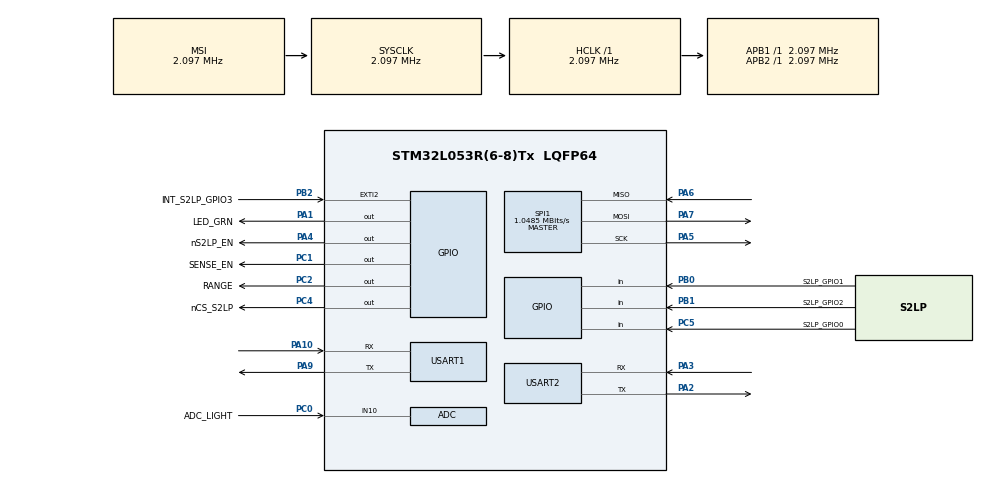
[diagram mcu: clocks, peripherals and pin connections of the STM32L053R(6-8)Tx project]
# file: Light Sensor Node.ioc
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Mcu.Family=STM32L0
Mcu.Name=STM32L053R(6-8)Tx
Mcu.Package=LQFP64
NVIC.EXTI2_3_IRQn=true\:0\:0\:false\:false\:true
NVIC.SPI1_IRQn=true\:0\:0\:false\:false\:true
PA1.GPIO_Label=LED_GRN
PA1.Signal=GPIO_Output
PA10.Mode=Asynchronous
PA10.Signal=USART1_RX
PA13.Mode=Serial_Wire
PA13.Signal=SYS_SWDIO
PA14.Mode=Serial_Wire
PA14.Signal=SYS_SWCLK
PA2.Mode=Asynchronous
PA2.Signal=USART2_TX
PA3.Mode=Asynchronous
PA3.Signal=USART2_RX
PA4.GPIO_Label=nS2LP_EN
PA4.Signal=GPIO_Output
PA5.Mode=Full_Duplex_Master
PA5.Signal=SPI1_SCK
PA6.Mode=Full_Duplex_Master
PA6.Signal=SPI1_MISO
PA7.Mode=Full_Duplex_Master
PA7.Signal=SPI1_MOSI
PA9.Mode=Asynchronous
PA9.Signal=USART1_TX
PB0.GPIO_Label=S2LP_GPIO1
PB0.Signal=GPIO_Input
PB1.GPIO_Label=S2LP_GPIO2
PB1.Signal=GPIO_Input
PB2.GPIO_Label=INT_S2LP_GPIO3
PB2.GPIO_ModeDefaultEXTI=GPIO_MODE_IT_FALLING
PB2.GPIO_PuPd=GPIO_PULLUP
PB2.Signal=GPXTI2
PC0.GPIO_Label=ADC_LIGHT
PC0.Mode=IN10
PC0.Signal=ADC_IN10
PC1.GPIO_Label=SENSE_EN
PC1.Signal=GPIO_Output
PC14-OSC32_IN.Mode=LSE-External-Oscillator
PC14-OSC32_IN.Signal=RCC_OSC32_IN
PC15-OSC32_OUT.Mode=LSE-External-Oscillator
PC15-OSC32_OUT.Signal=RCC_OSC32_OUT
PC2.GPIO_Label=RANGE
PC2.Signal=GPIO_Output
PC4.GPIO_Label=nCS_S2LP
PC4.PinState=GPIO_PIN_SET
PC4.Signal=GPIO_Output
PC5.GPIO_Label=S2LP_GPIO0
PC5.Signal=GPIO_Input
ProjectManager.HeapSize=0x200
ProjectManager.StackSize=0x400
ProjectManager.TargetToolchain=MDK-ARM V5
RCC.AHBFreq_Value=2097000
RCC.APB1Freq_Value=2097000
RCC.APB1TimFreq_Value=2097000
RCC.APB2Freq_Value=2097000
RCC.APB2TimFreq_Value=2097000
RCC.HSE_VALUE=8000000
RCC.HSI16_VALUE=16000000
RCC.HSI48_VALUE=48000000
RCC.HSI_VALUE=16000000
RCC.MSI_VALUE=2097000
RCC.RTCClockSelection=RCC_RTCCLKSOURCE_LSE
RCC.RTCClockSelectionVirtual=RCC_RTCCLKSOURCE_LSE
RCC.SYSCLKFreq_VALUE=2097000
RCC.VCOOutputFreq_Value=48000000
SPI1.CalculateBaudRate=1.0485 MBits/s
SPI1.Direction=SPI_DIRECTION_2LINES
SPI1.Mode=SPI_MODE_MASTER
SPI1.VirtualType=VM_MASTER
USART1.VirtualMode-Asynchronous=VM_ASYNC
USART1.WordLength=WORDLENGTH_8B
USART2.VirtualMode-Asynchronous=VM_ASYNC
USART2.WordLength=WORDLENGTH_8B
VP_ADC_TempSens_Input.Mode=IN-TempSens
VP_ADC_Vref_Input.Mode=IN-Vrefint
VP_RTC_VS_RTC_Activate.Mode=RTC_Enabled
VP_RTC_VS_RTC_Calendar.Mode=RTC_Calendar
board=Light Sensor Node

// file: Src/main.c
/**
  ******************************************************************************
  * File Name          : main.c
  * Description        : Main program body
  ******************************************************************************
  ** This notice applies to any and all portions of this file
  * that are not between comment pairs USER CODE BEGIN and
  * USER CODE END. Other portions of this file, whether
  * inserted by the user or by software development tools
  * are owned by their respective copyright owners.
  *
  * COPYRIGHT(c) 2018 STMicroelectronics
  *
  * Redistribution and use in source and binary forms, with or without modification,
  * are permitted provided that the following conditions are met:
  *   1. Redistributions of source code must retain the above copyright notice,
  *      this list of conditions and the following disclaimer.
  *   2. Redistributions in binary form must reproduce the above copyright notice,
  *      this list of conditions and the following disclaimer in the documentation
  *      and/or other materials provided with the distribution.
  *   3. Neither the name of STMicroelectronics nor the names of its contributors
  *      may be used to endorse or promote products derived from this software
  *      without specific prior written permission.
  *
  * THIS SOFTWARE IS PROVIDED BY THE COPYRIGHT HOLDERS AND CONTRIBUTORS "AS IS"
  * AND ANY EXPRESS OR IMPLIED WARRANTIES, INCLUDING, BUT NOT LIMITED TO, THE
  * IMPLIED WARRANTIES OF MERCHANTABILITY AND FITNESS FOR A PARTICULAR PURPOSE ARE
  * DISCLAIMED. IN NO EVENT SHALL THE COPYRIGHT HOLDER OR CONTRIBUTORS BE LIABLE
  * FOR ANY DIRECT, INDIRECT, INCIDENTAL, SPECIAL, EXEMPLARY, OR CONSEQUENTIAL
  * DAMAGES (INCLUDING, BUT NOT LIMITED TO, PROCUREMENT OF SUBSTITUTE GOODS OR
  * SERVICES; LOSS OF USE, DATA, OR PROFITS; OR BUSINESS INTERRUPTION) HOWEVER
  * CAUSED AND ON ANY THEORY OF LIABILITY, WHETHER IN CONTRACT, STRICT LIABILITY,
  * OR TORT (INCLUDING NEGLIGENCE OR OTHERWISE) ARISING IN ANY WAY OUT OF THE USE
  * OF THIS SOFTWARE, EVEN IF ADVISED OF THE POSSIBILITY OF SUCH DAMAGE.
  *
  ******************************************************************************
  */
#include "main.h"
#include "stm32l0xx_hal.h"

/* USER CODE BEGIN Includes */
#include "mg_S2lpTopLevel.h"

/* USER CODE END Includes */

ADC_HandleTypeDef hadc;

RTC_HandleTypeDef hrtc;

SPI_HandleTypeDef hspi1;

UART_HandleTypeDef huart1;
UART_HandleTypeDef huart2;

/* USER CODE BEGIN PV */
/* Private variables ---------------------------------------------------------*/

/* USER CODE END PV */

void SystemClock_Config(void);
static void MX_GPIO_Init(void);
static void MX_ADC_Init(void);
static void MX_SPI1_Init(void);
static void MX_USART1_UART_Init(void);
static void MX_RTC_Init(void);
static void MX_USART2_UART_Init(void);

/* USER CODE BEGIN PFP */
/* Private function prototypes -----------------------------------------------*/

/* USER CODE END PFP */

int main(void)
{

  /* MCU Configuration----------------------------------------------------------*/

  /* Reset of all peripherals, Initializes the Flash interface and the Systick. */
  HAL_Init();

  /* Configure the system clock */
  SystemClock_Config();

  /* Initialize all configured peripherals */
  MX_GPIO_Init();
  MX_ADC_Init();
  MX_SPI1_Init();
  MX_USART1_UART_Init();
  MX_RTC_Init();
  MX_USART2_UART_Init();

  /* USER CODE BEGIN 2 */

	TopLevel();

  /* USER CODE END 2 */

  /* Infinite loop */
  while (1)
  {

  }

}

/** System Clock Configuration
*/
void SystemClock_Config(void)
{

  RCC_OscInitTypeDef RCC_OscInitStruct;
  RCC_ClkInitTypeDef RCC_ClkInitStruct;
  RCC_PeriphCLKInitTypeDef PeriphClkInit;

    /**Configure the main internal regulator output voltage
    */
  __HAL_PWR_VOLTAGESCALING_CONFIG(PWR_REGULATOR_VOLTAGE_SCALE1);

    /**Configure LSE Drive Capability
    */
  __HAL_RCC_LSEDRIVE_CONFIG(RCC_LSEDRIVE_LOW);

    /**Initializes the CPU, AHB and APB busses clocks
    */
  RCC_OscInitStruct.OscillatorType = RCC_OSCILLATORTYPE_LSE|RCC_OSCILLATORTYPE_MSI;
  RCC_OscInitStruct.LSEState = RCC_LSE_ON;
  RCC_OscInitStruct.MSIState = RCC_MSI_ON;
  RCC_OscInitStruct.MSICalibrationValue = 0;
  RCC_OscInitStruct.MSIClockRange = RCC_MSIRANGE_5;
  RCC_OscInitStruct.PLL.PLLState = RCC_PLL_NONE;
  if (HAL_RCC_OscConfig(&RCC_OscInitStruct) != HAL_OK)
  {
    _Error_Handler(__FILE__, __LINE__);
  }

    /**Initializes the CPU, AHB and APB busses clocks
    */
  RCC_ClkInitStruct.ClockType = RCC_CLOCKTYPE_HCLK|RCC_CLOCKTYPE_SYSCLK
                              |RCC_CLOCKTYPE_PCLK1|RCC_CLOCKTYPE_PCLK2;
  RCC_ClkInitStruct.SYSCLKSource = RCC_SYSCLKSOURCE_MSI;
  RCC_ClkInitStruct.AHBCLKDivider = RCC_SYSCLK_DIV1;
  RCC_ClkInitStruct.APB1CLKDivider = RCC_HCLK_DIV1;
  RCC_ClkInitStruct.APB2CLKDivider = RCC_HCLK_DIV1;

  if (HAL_RCC_ClockConfig(&RCC_ClkInitStruct, FLASH_LATENCY_0) != HAL_OK)
  {
    _Error_Handler(__FILE__, __LINE__);
  }

  PeriphClkInit.PeriphClockSelection = RCC_PERIPHCLK_USART1|RCC_PERIPHCLK_USART2
                              |RCC_PERIPHCLK_RTC;
  PeriphClkInit.Usart1ClockSelection = RCC_USART1CLKSOURCE_PCLK2;
  PeriphClkInit.Usart2ClockSelection = RCC_USART2CLKSOURCE_PCLK1;
  PeriphClkInit.RTCClockSelection = RCC_RTCCLKSOURCE_LSE;
  if (HAL_RCCEx_PeriphCLKConfig(&PeriphClkInit) != HAL_OK)
  {
    _Error_Handler(__FILE__, __LINE__);
  }

    /**Configure the Systick interrupt time
    */
  HAL_SYSTICK_Config(HAL_RCC_GetHCLKFreq()/1000);

    /**Configure the Systick
    */
  HAL_SYSTICK_CLKSourceConfig(SYSTICK_CLKSOURCE_HCLK);

  /* SysTick_IRQn interrupt configuration */
  HAL_NVIC_SetPriority(SysTick_IRQn, 0, 0);
}

/* ADC init function */
static void MX_ADC_Init(void)
{

  ADC_ChannelConfTypeDef sConfig;

    /**Configure the global features of the ADC (Clock, Resolution, Data Alignment and number of conversion)
    */
  hadc.Instance = ADC1;
  hadc.Init.OversamplingMode = DISABLE;
  hadc.Init.ClockPrescaler = ADC_CLOCK_SYNC_PCLK_DIV1;
  hadc.Init.Resolution = ADC_RESOLUTION_12B;
  hadc.Init.SamplingTime = ADC_SAMPLETIME_1CYCLE_5;
  hadc.Init.ScanConvMode = ADC_SCAN_DIRECTION_FORWARD;
  hadc.Init.DataAlign = ADC_DATAALIGN_RIGHT;
  hadc.Init.ContinuousConvMode = DISABLE;
  hadc.Init.DiscontinuousConvMode = DISABLE;
  hadc.Init.ExternalTrigConvEdge = ADC_EXTERNALTRIGCONVEDGE_NONE;
  hadc.Init.ExternalTrigConv = ADC_SOFTWARE_START;
  hadc.Init.DMAContinuousRequests = DISABLE;
  hadc.Init.EOCSelection = ADC_EOC_SINGLE_CONV;
  hadc.Init.Overrun = ADC_OVR_DATA_PRESERVED;
  hadc.Init.LowPowerAutoWait = DISABLE;
  hadc.Init.LowPowerFrequencyMode = DISABLE;
  hadc.Init.LowPowerAutoPowerOff = DISABLE;
  if (HAL_ADC_Init(&hadc) != HAL_OK)
  {
    _Error_Handler(__FILE__, __LINE__);
  }

    /**Configure for the selected ADC regular channel to be converted.
    */
  sConfig.Channel = ADC_CHANNEL_10;
  sConfig.Rank = ADC_RANK_CHANNEL_NUMBER;
  if (HAL_ADC_ConfigChannel(&hadc, &sConfig) != HAL_OK)
  {
    _Error_Handler(__FILE__, __LINE__);
  }

    /**Configure for the selected ADC regular channel to be converted.
    */
  sConfig.Channel = ADC_CHANNEL_TEMPSENSOR;
  if (HAL_ADC_ConfigChannel(&hadc, &sConfig) != HAL_OK)
  {
    _Error_Handler(__FILE__, __LINE__);
  }

    /**Configure for the selected ADC regular channel to be converted.
    */
  sConfig.Channel = ADC_CHANNEL_VREFINT;
  if (HAL_ADC_ConfigChannel(&hadc, &sConfig) != HAL_OK)
  {
    _Error_Handler(__FILE__, __LINE__);
  }

}

/* RTC init function */
static void MX_RTC_Init(void)
{

  RTC_TimeTypeDef sTime;
  RTC_DateTypeDef sDate;

    /**Initialize RTC Only
    */
  hrtc.Instance = RTC;
  hrtc.Init.HourFormat = RTC_HOURFORMAT_24;
  hrtc.Init.AsynchPrediv = 127;
  hrtc.Init.SynchPrediv = 255;
  hrtc.Init.OutPut = RTC_OUTPUT_DISABLE;
  hrtc.Init.OutPutRemap = RTC_OUTPUT_REMAP_NONE;
  hrtc.Init.OutPutPolarity = RTC_OUTPUT_POLARITY_HIGH;
  hrtc.Init.OutPutType = RTC_OUTPUT_TYPE_OPENDRAIN;
  if (HAL_RTC_Init(&hrtc) != HAL_OK)
  {
    _Error_Handler(__FILE__, __LINE__);
  }

    /**Initialize RTC and set the Time and Date
    */
  if(HAL_RTCEx_BKUPRead(&hrtc, RTC_BKP_DR0) != 0x32F2){
  sTime.Hours = 0x0;
  sTime.Minutes = 0x0;
  sTime.Seconds = 0x0;
  sTime.DayLightSaving = RTC_DAYLIGHTSAVING_NONE;
  sTime.StoreOperation = RTC_STOREOPERATION_RESET;
  if (HAL_RTC_SetTime(&hrtc, &sTime, RTC_FORMAT_BCD) != HAL_OK)
  {
    _Error_Handler(__FILE__, __LINE__);
  }

  sDate.WeekDay = RTC_WEEKDAY_MONDAY;
  sDate.Month = RTC_MONTH_JANUARY;
  sDate.Date = 0x1;
  sDate.Year = 0x0;

  if (HAL_RTC_SetDate(&hrtc, &sDate, RTC_FORMAT_BCD) != HAL_OK)
  {
    _Error_Handler(__FILE__, __LINE__);
  }

    HAL_RTCEx_BKUPWrite(&hrtc,RTC_BKP_DR0,0x32F2);
  }

}

/* SPI1 init function */
static void MX_SPI1_Init(void)
{

  hspi1.Instance = SPI1;
  hspi1.Init.Mode = SPI_MODE_MASTER;
  hspi1.Init.Direction = SPI_DIRECTION_2LINES;
  hspi1.Init.DataSize = SPI_DATASIZE_8BIT;
  hspi1.Init.CLKPolarity = SPI_POLARITY_LOW;
  hspi1.Init.CLKPhase = SPI_PHASE_1EDGE;
  hspi1.Init.NSS = SPI_NSS_SOFT;
  hspi1.Init.BaudRatePrescaler = SPI_BAUDRATEPRESCALER_2;
  hspi1.Init.FirstBit = SPI_FIRSTBIT_MSB;
  hspi1.Init.TIMode = SPI_TIMODE_DISABLE;
  hspi1.Init.CRCCalculation = SPI_CRCCALCULATION_DISABLE;
  hspi1.Init.CRCPolynomial = 7;
  if (HAL_SPI_Init(&hspi1) != HAL_OK)
  {
    _Error_Handler(__FILE__, __LINE__);
  }

}

/* USART1 init function */
static void MX_USART1_UART_Init(void)
{

  huart1.Instance = USART1;
  huart1.Init.BaudRate = 115200;
  huart1.Init.WordLength = UART_WORDLENGTH_8B;
  huart1.Init.StopBits = UART_STOPBITS_1;
  huart1.Init.Parity = UART_PARITY_NONE;
  huart1.Init.Mode = UART_MODE_TX_RX;
  huart1.Init.HwFlowCtl = UART_HWCONTROL_NONE;
  huart1.Init.OverSampling = UART_OVERSAMPLING_16;
  huart1.Init.OneBitSampling = UART_ONE_BIT_SAMPLE_DISABLE;
  huart1.AdvancedInit.AdvFeatureInit = UART_ADVFEATURE_NO_INIT;
  if (HAL_UART_Init(&huart1) != HAL_OK)
  {
    _Error_Handler(__FILE__, __LINE__);
  }

}

/* USART2 init function */
static void MX_USART2_UART_Init(void)
{

  huart2.Instance = USART2;
  huart2.Init.BaudRate = 115200;
  huart2.Init.WordLength = UART_WORDLENGTH_8B;
  huart2.Init.StopBits = UART_STOPBITS_1;
  huart2.Init.Parity = UART_PARITY_NONE;
  huart2.Init.Mode = UART_MODE_TX_RX;
  huart2.Init.HwFlowCtl = UART_HWCONTROL_NONE;
  huart2.Init.OverSampling = UART_OVERSAMPLING_16;
  huart2.Init.OneBitSampling = UART_ONE_BIT_SAMPLE_DISABLE;
  huart2.AdvancedInit.AdvFeatureInit = UART_ADVFEATURE_NO_INIT;
  if (HAL_UART_Init(&huart2) != HAL_OK)
  {
    _Error_Handler(__FILE__, __LINE__);
  }

}

/** Configure pins as
        * Analog
        * Input
        * Output
        * EVENT_OUT
        * EXTI
*/
static void MX_GPIO_Init(void)
{

  GPIO_InitTypeDef GPIO_InitStruct;

  /* GPIO Ports Clock Enable */
  __HAL_RCC_GPIOC_CLK_ENABLE();
  __HAL_RCC_GPIOA_CLK_ENABLE();
  __HAL_RCC_GPIOB_CLK_ENABLE();

  /*Configure GPIO pin Output Level */
  HAL_GPIO_WritePin(GPIOC, SENSE_EN_Pin|RANGE_Pin, GPIO_PIN_RESET);

  /*Configure GPIO pin Output Level */
  HAL_GPIO_WritePin(GPIOA, LED_GRN_Pin|nS2LP_EN_Pin, GPIO_PIN_RESET);

  /*Configure GPIO pin Output Level */
  HAL_GPIO_WritePin(nCS_S2LP_GPIO_Port, nCS_S2LP_Pin, GPIO_PIN_SET);

  /*Configure GPIO pins : SENSE_EN_Pin RANGE_Pin nCS_S2LP_Pin */
  GPIO_InitStruct.Pin = SENSE_EN_Pin|RANGE_Pin|nCS_S2LP_Pin;
  GPIO_InitStruct.Mode = GPIO_MODE_OUTPUT_PP;
  GPIO_InitStruct.Pull = GPIO_NOPULL;
  GPIO_InitStruct.Speed = GPIO_SPEED_FREQ_LOW;
  HAL_GPIO_Init(GPIOC, &GPIO_InitStruct);

  /*Configure GPIO pins : LED_GRN_Pin nS2LP_EN_Pin */
  GPIO_InitStruct.Pin = LED_GRN_Pin|nS2LP_EN_Pin;
  GPIO_InitStruct.Mode = GPIO_MODE_OUTPUT_PP;
  GPIO_InitStruct.Pull = GPIO_NOPULL;
  GPIO_InitStruct.Speed = GPIO_SPEED_FREQ_LOW;
  HAL_GPIO_Init(GPIOA, &GPIO_InitStruct);

  /*Configure GPIO pin : S2LP_GPIO0_Pin */
  GPIO_InitStruct.Pin = S2LP_GPIO0_Pin;
  GPIO_InitStruct.Mode = GPIO_MODE_INPUT;
  GPIO_InitStruct.Pull = GPIO_NOPULL;
  HAL_GPIO_Init(S2LP_GPIO0_GPIO_Port, &GPIO_InitStruct);

  /*Configure GPIO pins : S2LP_GPIO1_Pin S2LP_GPIO2_Pin */
  GPIO_InitStruct.Pin = S2LP_GPIO1_Pin|S2LP_GPIO2_Pin;
  GPIO_InitStruct.Mode = GPIO_MODE_INPUT;
  GPIO_InitStruct.Pull = GPIO_NOPULL;
  HAL_GPIO_Init(GPIOB, &GPIO_InitStruct);

  /*Configure GPIO pin : INT_S2LP_GPIO3_Pin */
  GPIO_InitStruct.Pin = INT_S2LP_GPIO3_Pin;
  GPIO_InitStruct.Mode = GPIO_MODE_IT_FALLING;
  GPIO_InitStruct.Pull = GPIO_PULLUP;
  HAL_GPIO_Init(INT_S2LP_GPIO3_GPIO_Port, &GPIO_InitStruct);

  /* EXTI interrupt init*/
  HAL_NVIC_SetPriority(EXTI2_3_IRQn, 0, 0);
  HAL_NVIC_EnableIRQ(EXTI2_3_IRQn);

}

void _Error_Handler(char * file, int line)
{
  while(1)
  {
  }
}

/************************ (C) COPYRIGHT STMicroelectronics *****END OF FILE****/
